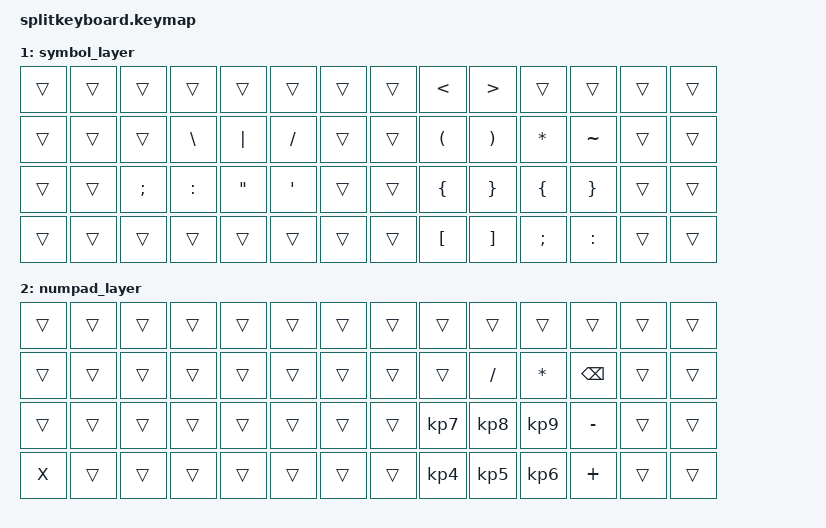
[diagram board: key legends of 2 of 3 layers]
/*
 * Copyright (c) 2020 The ZMK Contributors
 *
 * SPDX-License-Identifier: MIT
 */


#include <behaviors.dtsi>
#include <dt-bindings/zmk/keys.h>
#include <dt-bindings/zmk/bt.h>
#include <locale/keys_se.h>


#define DEFAULT 0
#define LOWER   1
#define RAISE   2

/ {
    keymap {
        compatible = "zmk,keymap";

        default_layer {
            bindings = <
&mt ESC SINGLE_QUOTE  &kp N1     &kp N1     &kp N2    &kp N3    &kp N4         &kp N5         &kp SE_LBKT  &kp N7         &kp N8     &kp N9    &kp N0     &kp APOS  &mt DELETE BACKSPACE
&kp E                 &kp TAB    &kp Q      &kp W     &kp W     &kp R          &kp T          &kp Y        &kp U          &kp I      &kp O     &kp P      &kp LBKT  &kp ENTER
&bt BT_SEL 0          &kp CAPS   &kp A      &kp S     &kp D     &kp F          &kp G          &kp H        &kp J          &kp K      &kp L     &kp SEMI   &kp APOS  &kp MINUS
&bt BT_SEL 1          &kp LSHFT  &kp Z      &kp X     &kp C     &kp V          &kp B          &kp N        &kp M          &kp COMMA  &kp DOT   &kp MINUS  &kp UP    &kp RIGHT
&trans                &kp UP     &kp LCTRL  &kp LALT  &kp LGUI  &mo LOWER      &lt 1 SPACE    &lt 1 SPACE  &mo RAISE      &kp RGUI   &kp RALT  &kp LEFT   &kp DOWN  &kp RIGHT
            >;
        };

        symbol_layer {
            bindings = <
&trans  &trans  &trans         &trans         &trans             &trans     &trans    &trans  &kp LESS_THAN         &kp GREATER_THAN       &trans          &trans           &trans  &trans
&trans  &trans  &trans         &kp BACKSLASH  &kp PIPE           &kp SLASH  &trans    &trans  &kp LEFT_PARENTHESIS  &kp RIGHT_PARENTHESIS  &kp ASTERISK    &kp TILDE        &trans  &trans
&trans  &trans  &kp SEMICOLON  &kp COLON      &kp DOUBLE_QUOTES  &kp SQT    &trans    &trans  &kp LEFT_BRACE        &kp RIGHT_BRACE        &kp LEFT_BRACE  &kp RIGHT_BRACE  &trans  &trans
&trans  &trans  &trans         &trans         &trans             &trans     &trans    &trans  &kp LEFT_BRACKET      &kp RIGHT_BRACKET      &kp SEMICOLON   &kp COLON        &trans  &trans
            >;
        };

        numpad_layer {
            bindings = <
&trans  &trans  &trans  &trans  &trans  &trans  &trans    &trans  &trans           &trans           &trans           &trans         &trans  &trans
&trans  &trans  &trans  &trans  &trans  &trans  &trans    &trans  &trans           &kp SLASH        &kp ASTERISK     &kp BACKSPACE  &trans  &trans
&trans  &trans  &trans  &trans  &trans  &trans  &trans    &trans  &kp KP_NUMBER_7  &kp KP_NUMBER_8  &kp KP_NUMBER_9  &kp MINUS      &trans  &trans
&kp X  &trans  &trans  &trans  &trans  &trans  &trans    &trans  &kp KP_NUMBER_4  &kp KP_NUMBER_5  &kp KP_NUMBER_6  &kp PLUS       &trans  &trans
            >;
        };
    };
};
